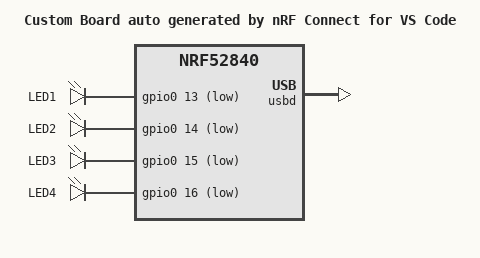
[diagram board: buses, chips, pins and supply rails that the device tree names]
/dts-v1/;
#include <nordic/nrf52840_qiaa.dtsi>
#include <zephyr/dt-bindings/gpio/gpio.h>
#include "nu40dk-pinctrl.dtsi"

/ {
	model = "Custom Board auto generated by nRF Connect for VS Code";
	compatible = "nucode,nu40dk";

	chosen {
		zephyr,sram = &sram0;
		zephyr,flash = &flash0;
		zephyr,code-partition = &slot0_partition;
		// USB CDC 인스턴스를 부팅시 자동 등록시키기 위한 지정.
		// (콘솔 서브시스템은 쓰지 않고 UART 드라이버 API 로 직접 접근한다)
		//
		zephyr,console = &cdc_acm_uart0;
	};

  leds {
    compatible = "gpio-leds";
    led1: led1 {
      gpios = <&gpio0 13 GPIO_ACTIVE_LOW>;
      label = "LED1";
    };
    led2: led2 {
      gpios = <&gpio0 14 GPIO_ACTIVE_LOW>;
      label = "LED2";
    };
    led3: led3 {
      gpios = <&gpio0 15 GPIO_ACTIVE_LOW>;
      label = "LED3";
    };
    led4: led4 {
      gpios = <&gpio0 16 GPIO_ACTIVE_LOW>;
      label = "LED4";
    };
  };
};

&flash0 {
	partitions {
		compatible = "fixed-partitions";
		#address-cells = <1>;
		#size-cells = <1>;

		boot_partition: partition@0 {
			label = "mcuboot";
			reg = <0x00000000 DT_SIZE_K(48)>;
		};

		slot0_partition: partition@c000 {
			label = "image-0";
			reg = <0x0000c000 DT_SIZE_K(472)>;
		};

		slot1_partition: partition@82000 {
			label = "image-1";
			reg = <0x00082000 DT_SIZE_K(472)>;
		};

		storage_partition: partition@f8000 {
			label = "storage";
			reg = <0x000f8000 DT_SIZE_K(32)>;
		};
	};
};

// CLI 용 USB CDC. 보드에 UART 커넥터가 없고 디버그 커넥터(J4)에도 UART 선이
// 없으므로 네이티브 USB 를 사용한다.
//
zephyr_udc0: &usbd {
  status = "okay";

  cdc_acm_uart0: cdc_acm_uart0 {
    compatible = "zephyr,cdc-acm-uart";
  };
};

&gpio0 {
  status = "okay";
};

&gpiote {
  status = "okay";
};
